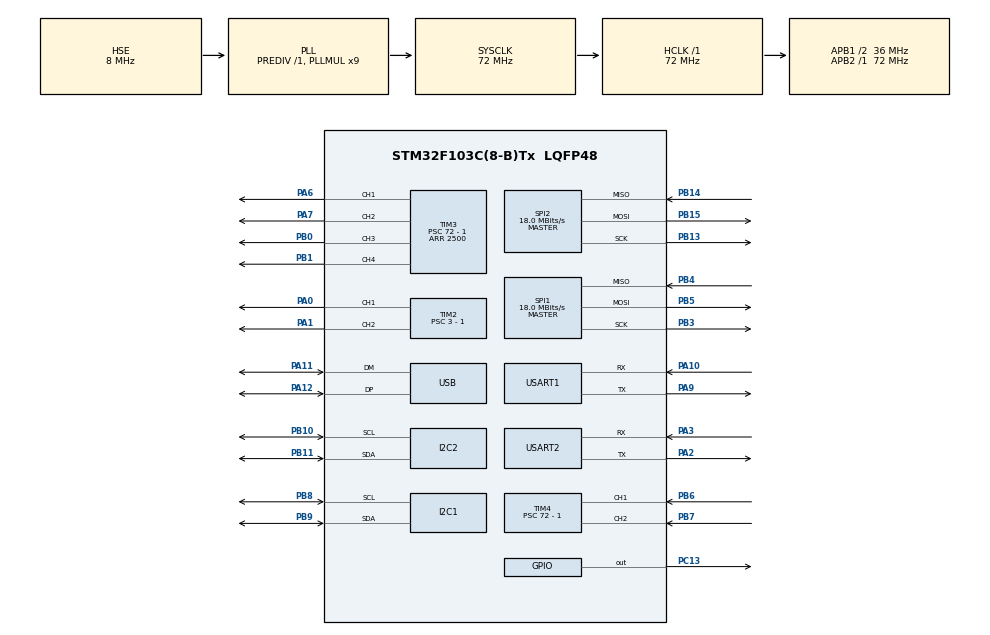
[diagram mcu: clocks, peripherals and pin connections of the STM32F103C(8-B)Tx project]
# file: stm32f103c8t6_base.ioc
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Dma.I2C1_TX.2.Direction=DMA_MEMORY_TO_PERIPH
Dma.I2C1_TX.2.Instance=DMA1_Channel6
Dma.I2C1_TX.2.MemDataAlignment=DMA_MDATAALIGN_BYTE
Dma.I2C1_TX.2.MemInc=DMA_MINC_ENABLE
Dma.I2C1_TX.2.Mode=DMA_NORMAL
Dma.I2C1_TX.2.PeriphDataAlignment=DMA_PDATAALIGN_BYTE
Dma.I2C1_TX.2.PeriphInc=DMA_PINC_DISABLE
Dma.I2C1_TX.2.Priority=DMA_PRIORITY_LOW
Dma.I2C2_TX.3.Direction=DMA_MEMORY_TO_PERIPH
Dma.I2C2_TX.3.Instance=DMA1_Channel4
Dma.I2C2_TX.3.MemDataAlignment=DMA_MDATAALIGN_BYTE
Dma.I2C2_TX.3.MemInc=DMA_MINC_ENABLE
Dma.I2C2_TX.3.Mode=DMA_NORMAL
Dma.I2C2_TX.3.PeriphDataAlignment=DMA_PDATAALIGN_BYTE
Dma.I2C2_TX.3.PeriphInc=DMA_PINC_DISABLE
Dma.I2C2_TX.3.Priority=DMA_PRIORITY_LOW
Dma.Request0=SPI1_RX
Dma.Request1=SPI1_TX
Dma.Request2=I2C1_TX
Dma.Request3=I2C2_TX
Dma.Request4=TIM2_CH1
Dma.Request5=TIM2_CH2/CH4
Dma.SPI1_RX.0.Direction=DMA_PERIPH_TO_MEMORY
Dma.SPI1_RX.0.Instance=DMA1_Channel2
Dma.SPI1_RX.0.MemDataAlignment=DMA_MDATAALIGN_BYTE
Dma.SPI1_RX.0.MemInc=DMA_MINC_ENABLE
Dma.SPI1_RX.0.Mode=DMA_NORMAL
Dma.SPI1_RX.0.PeriphDataAlignment=DMA_PDATAALIGN_BYTE
Dma.SPI1_RX.0.PeriphInc=DMA_PINC_DISABLE
Dma.SPI1_RX.0.Priority=DMA_PRIORITY_LOW
Dma.SPI1_TX.1.Direction=DMA_MEMORY_TO_PERIPH
Dma.SPI1_TX.1.Instance=DMA1_Channel3
Dma.SPI1_TX.1.MemDataAlignment=DMA_MDATAALIGN_BYTE
Dma.SPI1_TX.1.MemInc=DMA_MINC_ENABLE
Dma.SPI1_TX.1.Mode=DMA_NORMAL
Dma.SPI1_TX.1.PeriphDataAlignment=DMA_PDATAALIGN_BYTE
Dma.SPI1_TX.1.PeriphInc=DMA_PINC_DISABLE
Dma.SPI1_TX.1.Priority=DMA_PRIORITY_LOW
Dma.TIM2_CH1.4.Direction=DMA_MEMORY_TO_PERIPH
Dma.TIM2_CH1.4.Instance=DMA1_Channel5
Dma.TIM2_CH1.4.MemDataAlignment=DMA_MDATAALIGN_BYTE
Dma.TIM2_CH1.4.MemInc=DMA_MINC_ENABLE
Dma.TIM2_CH1.4.Mode=DMA_NORMAL
Dma.TIM2_CH1.4.PeriphDataAlignment=DMA_PDATAALIGN_HALFWORD
Dma.TIM2_CH1.4.PeriphInc=DMA_PINC_DISABLE
Dma.TIM2_CH1.4.Priority=DMA_PRIORITY_LOW
Dma.TIM2_CH2/CH4.5.Direction=DMA_MEMORY_TO_PERIPH
Dma.TIM2_CH2/CH4.5.Instance=DMA1_Channel7
Dma.TIM2_CH2/CH4.5.MemDataAlignment=DMA_MDATAALIGN_BYTE
Dma.TIM2_CH2/CH4.5.MemInc=DMA_MINC_ENABLE
Dma.TIM2_CH2/CH4.5.Mode=DMA_NORMAL
Dma.TIM2_CH2/CH4.5.PeriphDataAlignment=DMA_PDATAALIGN_HALFWORD
Dma.TIM2_CH2/CH4.5.PeriphInc=DMA_PINC_DISABLE
Dma.TIM2_CH2/CH4.5.Priority=DMA_PRIORITY_LOW
I2C1.I2C_Mode=I2C_Fast
I2C2.I2C_Mode=I2C_Fast
Mcu.Family=STM32F1
Mcu.Name=STM32F103C(8-B)Tx
Mcu.Package=LQFP48
NVIC.DMA1_Channel2_IRQn=true\:0\:0\:false\:false\:true
NVIC.DMA1_Channel3_IRQn=true\:0\:0\:false\:false\:true
NVIC.DMA1_Channel4_IRQn=true\:0\:0\:false\:false\:true
NVIC.DMA1_Channel5_IRQn=true\:0\:0\:false\:false\:true
NVIC.DMA1_Channel6_IRQn=true\:0\:0\:false\:false\:true
NVIC.DMA1_Channel7_IRQn=true\:0\:0\:false\:false\:true
NVIC.I2C1_ER_IRQn=true\:0\:0\:false\:false\:true
NVIC.I2C1_EV_IRQn=true\:0\:0\:false\:false\:true
NVIC.I2C2_ER_IRQn=true\:0\:0\:false\:false\:true
NVIC.I2C2_EV_IRQn=true\:0\:0\:false\:false\:true
NVIC.PriorityGroup=NVIC_PRIORITYGROUP_4
NVIC.SPI2_IRQn=true\:0\:0\:false\:false\:true
NVIC.TIM4_IRQn=true\:0\:0\:false\:false\:true
NVIC.USART1_IRQn=true\:0\:0\:false\:false\:true
NVIC.USART2_IRQn=true\:0\:0\:false\:false\:true
NVIC.USB_LP_CAN1_RX0_IRQn=true\:0\:0\:false\:false\:true
PA0-WKUP.Signal=S_TIM2_CH1_ETR
PA1.Signal=S_TIM2_CH2
PA10.Mode=Asynchronous
PA10.Signal=USART1_RX
PA11.Mode=Device
PA11.Signal=USB_DM
PA12.Mode=Device
PA12.Signal=USB_DP
PA13.Mode=Serial_Wire
PA13.Signal=SYS_JTMS-SWDIO
PA14.Mode=Serial_Wire
PA14.Signal=SYS_JTCK-SWCLK
PA2.Mode=Asynchronous
PA2.Signal=USART2_TX
PA3.Mode=Asynchronous
PA3.Signal=USART2_RX
PA6.Signal=S_TIM3_CH1
PA7.Signal=S_TIM3_CH2
PA9.Mode=Asynchronous
PA9.Signal=USART1_TX
PB0.Signal=S_TIM3_CH3
PB1.Signal=S_TIM3_CH4
PB10.Mode=I2C
PB10.Signal=I2C2_SCL
PB11.Mode=I2C
PB11.Signal=I2C2_SDA
PB13.Mode=Full_Duplex_Master
PB13.Signal=SPI2_SCK
PB14.Mode=Full_Duplex_Master
PB14.Signal=SPI2_MISO
PB15.Mode=Full_Duplex_Master
PB15.Signal=SPI2_MOSI
PB3.Mode=Full_Duplex_Master
PB3.Signal=SPI1_SCK
PB4.Mode=Full_Duplex_Master
PB4.Signal=SPI1_MISO
PB5.Mode=Full_Duplex_Master
PB5.Signal=SPI1_MOSI
PB6.Signal=S_TIM4_CH1
PB7.Signal=S_TIM4_CH2
PB8.Mode=I2C
PB8.Signal=I2C1_SCL
PB9.Mode=I2C
PB9.Signal=I2C1_SDA
PC13-TAMPER-RTC.Signal=GPIO_Output
PD0-OSC_IN.Mode=HSE-External-Oscillator
PD0-OSC_IN.Signal=RCC_OSC_IN
PD1-OSC_OUT.Mode=HSE-External-Oscillator
PD1-OSC_OUT.Signal=RCC_OSC_OUT
ProjectManager.HeapSize=0x200
ProjectManager.StackSize=0x400
ProjectManager.TargetToolchain=Makefile
RCC.AHBFreq_Value=72000000
RCC.APB1CLKDivider=RCC_HCLK_DIV2
RCC.APB1Freq_Value=36000000
RCC.APB1TimFreq_Value=72000000
RCC.APB2Freq_Value=72000000
RCC.APB2TimFreq_Value=72000000
RCC.HCLKFreq_Value=72000000
RCC.PLLMUL=RCC_PLL_MUL9
RCC.SYSCLKFreq_VALUE=72000000
RCC.SYSCLKSource=RCC_SYSCLKSOURCE_PLLCLK
RCC.USBFreq_Value=48000000
RCC.USBPrescaler=RCC_USBCLKSOURCE_PLL_DIV1_5
SH.S_TIM2_CH1_ETR.0=TIM2_CH1,PWM Generation1 CH1
SH.S_TIM2_CH2.0=TIM2_CH2,PWM Generation2 CH2
SH.S_TIM3_CH1.0=TIM3_CH1,PWM Generation1 CH1
SH.S_TIM3_CH2.0=TIM3_CH2,PWM Generation2 CH2
SH.S_TIM3_CH3.0=TIM3_CH3,PWM Generation3 CH3
SH.S_TIM3_CH4.0=TIM3_CH4,PWM Generation4 CH4
SH.S_TIM4_CH1.0=TIM4_CH1,Input_Capture1_from_TI1
SH.S_TIM4_CH2.0=TIM4_CH2,Input_Capture2_from_TI2
SPI1.BaudRatePrescaler=SPI_BAUDRATEPRESCALER_4
SPI1.CalculateBaudRate=18.0 MBits/s
SPI1.Direction=SPI_DIRECTION_2LINES
SPI1.Mode=SPI_MODE_MASTER
SPI1.VirtualType=VM_MASTER
SPI2.BaudRatePrescaler=SPI_BAUDRATEPRESCALER_2
SPI2.CalculateBaudRate=18.0 MBits/s
SPI2.Direction=SPI_DIRECTION_2LINES
SPI2.Mode=SPI_MODE_MASTER
SPI2.VirtualType=VM_MASTER
TIM1.AutoReloadPreload=TIM_AUTORELOAD_PRELOAD_ENABLE
TIM1.Period=65535
TIM1.Prescaler=72 - 1
TIM2.AutoReloadPreload=TIM_AUTORELOAD_PRELOAD_ENABLE
TIM2.Channel-PWM\ Generation1\ CH1=TIM_CHANNEL_1
TIM2.Channel-PWM\ Generation2\ CH2=TIM_CHANNEL_2
TIM2.Period=30 - 1
TIM2.Prescaler=3 - 1
TIM3.AutoReloadPreload=TIM_AUTORELOAD_PRELOAD_ENABLE
TIM3.Channel-PWM\ Generation1\ CH1=TIM_CHANNEL_1
TIM3.Channel-PWM\ Generation2\ CH2=TIM_CHANNEL_2
TIM3.Channel-PWM\ Generation3\ CH3=TIM_CHANNEL_3
TIM3.Channel-PWM\ Generation4\ CH4=TIM_CHANNEL_4
TIM3.Period=2500
TIM3.Prescaler=72 - 1
TIM4.Channel-Input_Capture1_from_TI1=TIM_CHANNEL_1
TIM4.Channel-Input_Capture2_from_TI2=TIM_CHANNEL_2
TIM4.Period=65535
TIM4.Prescaler=72 - 1
USART1.VirtualMode=VM_ASYNC
USART2.VirtualMode=VM_ASYNC
USB_DEVICE.CLASS_NAME_FS=CDC
USB_DEVICE.VirtualMode=Cdc
USB_DEVICE.VirtualModeFS=Cdc_FS
VP_TIM1_VS_ClockSourceINT.Mode=Internal
VP_TIM2_VS_ClockSourceINT.Mode=Internal
VP_TIM3_VS_ClockSourceINT.Mode=Internal
VP_TIM4_VS_ClockSourceINT.Mode=Internal
VP_USB_DEVICE_VS_USB_DEVICE_CDC_FS.Mode=CDC_FS
board=stm32f103c8t6_base

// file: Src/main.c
/**
  ******************************************************************************
  * File Name          : main.c
  * Description        : Main program body
  ******************************************************************************
  * This notice applies to any and all portions of this file
  * that are not between comment pairs USER CODE BEGIN and
  * USER CODE END. Other portions of this file, whether
  * inserted by the user or by software development tools
  * are owned by their respective copyright owners.
  *
  * Copyright (c) 2017 STMicroelectronics International N.V.
  * All rights reserved.
  *
  * Redistribution and use in source and binary forms, with or without
  * modification, are permitted, provided that the following conditions are met:
  *
  * 1. Redistribution of source code must retain the above copyright notice,
  *    this list of conditions and the following disclaimer.
  * 2. Redistributions in binary form must reproduce the above copyright notice,
  *    this list of conditions and the following disclaimer in the documentation
  *    and/or other materials provided with the distribution.
  * 3. Neither the name of STMicroelectronics nor the names of other
  *    contributors to this software may be used to endorse or promote products
  *    derived from this software without specific written permission.
  * 4. This software, including modifications and/or derivative works of this
  *    software, must execute solely and exclusively on microcontroller or
  *    microprocessor devices manufactured by or for STMicroelectronics.
  * 5. Redistribution and use of this software other than as permitted under
  *    this license is void and will automatically terminate your rights under
  *    this license.
  *
  * THIS SOFTWARE IS PROVIDED BY STMICROELECTRONICS AND CONTRIBUTORS "AS IS"
  * AND ANY EXPRESS, IMPLIED OR STATUTORY WARRANTIES, INCLUDING, BUT NOT
  * LIMITED TO, THE IMPLIED WARRANTIES OF MERCHANTABILITY, FITNESS FOR A
  * PARTICULAR PURPOSE AND NON-INFRINGEMENT OF THIRD PARTY INTELLECTUAL PROPERTY
  * RIGHTS ARE DISCLAIMED TO THE FULLEST EXTENT PERMITTED BY LAW. IN NO EVENT
  * SHALL STMICROELECTRONICS OR CONTRIBUTORS BE LIABLE FOR ANY DIRECT, INDIRECT,
  * INCIDENTAL, SPECIAL, EXEMPLARY, OR CONSEQUENTIAL DAMAGES (INCLUDING, BUT NOT
  * LIMITED TO, PROCUREMENT OF SUBSTITUTE GOODS OR SERVICES; LOSS OF USE, DATA,
  * OR PROFITS; OR BUSINESS INTERRUPTION) HOWEVER CAUSED AND ON ANY THEORY OF
  * LIABILITY, WHETHER IN CONTRACT, STRICT LIABILITY, OR TORT (INCLUDING
  * NEGLIGENCE OR OTHERWISE) ARISING IN ANY WAY OUT OF THE USE OF THIS SOFTWARE,
  * EVEN IF ADVISED OF THE POSSIBILITY OF SUCH DAMAGE.
  *
  ******************************************************************************
  */
#include "main.h"
#include "stm32f1xx_hal.h"
#include "dma.h"
#include "i2c.h"
#include "spi.h"
#include "tim.h"
#include "usart.h"
#include "usb_device.h"
#include "gpio.h"

#include "app.h"

/* USER CODE BEGIN PV */
/* Private variables ---------------------------------------------------------*/

/* USER CODE END PV */

void SystemClock_Config(void);

/* USER CODE BEGIN PFP */
/* Private function prototypes -----------------------------------------------*/

/* USER CODE END PFP */

int main(void)
{

  /* MCU Configuration----------------------------------------------------------*/

  /* Reset of all peripherals, Initializes the Flash interface and the Systick. */
  HAL_Init();

  app_init_f();

  /* Configure the system clock */
  SystemClock_Config();

  /* Initialize all configured peripherals */
  MX_GPIO_Init();
  MX_DMA_Init();
  MX_USART1_UART_Init();
  MX_USART2_UART_Init();
  MX_I2C1_Init();
  MX_SPI2_Init();
  MX_I2C2_Init();
  MX_TIM1_Init();
  MX_TIM3_Init();
  MX_SPI1_Init();
  MX_TIM2_Init();
  MX_TIM4_Init();
  MX_USB_DEVICE_Init();

  /* USER CODE BEGIN 2 */
  app_init_r();
  /* USER CODE END 2 */

  /* Infinite loop */
  /* USER CODE BEGIN WHILE */
  app_mainloop();
  /* USER CODE END WHILE */

}

/** System Clock Configuration
*/
void SystemClock_Config(void)
{

  RCC_OscInitTypeDef RCC_OscInitStruct;
  RCC_ClkInitTypeDef RCC_ClkInitStruct;
  RCC_PeriphCLKInitTypeDef PeriphClkInit;

    /**Initializes the CPU, AHB and APB busses clocks
    */
  RCC_OscInitStruct.OscillatorType = RCC_OSCILLATORTYPE_HSE;
  RCC_OscInitStruct.HSEState = RCC_HSE_ON;
  RCC_OscInitStruct.HSEPredivValue = RCC_HSE_PREDIV_DIV1;
  RCC_OscInitStruct.HSIState = RCC_HSI_ON;
  RCC_OscInitStruct.PLL.PLLState = RCC_PLL_ON;
  RCC_OscInitStruct.PLL.PLLSource = RCC_PLLSOURCE_HSE;
  RCC_OscInitStruct.PLL.PLLMUL = RCC_PLL_MUL9;
  if (HAL_RCC_OscConfig(&RCC_OscInitStruct) != HAL_OK)
  {
    _Error_Handler(__FILE__, __LINE__);
  }

    /**Initializes the CPU, AHB and APB busses clocks
    */
  RCC_ClkInitStruct.ClockType = RCC_CLOCKTYPE_HCLK|RCC_CLOCKTYPE_SYSCLK
                              |RCC_CLOCKTYPE_PCLK1|RCC_CLOCKTYPE_PCLK2;
  RCC_ClkInitStruct.SYSCLKSource = RCC_SYSCLKSOURCE_PLLCLK;
  RCC_ClkInitStruct.AHBCLKDivider = RCC_SYSCLK_DIV1;
  RCC_ClkInitStruct.APB1CLKDivider = RCC_HCLK_DIV2;
  RCC_ClkInitStruct.APB2CLKDivider = RCC_HCLK_DIV1;

  if (HAL_RCC_ClockConfig(&RCC_ClkInitStruct, FLASH_LATENCY_2) != HAL_OK)
  {
    _Error_Handler(__FILE__, __LINE__);
  }

  PeriphClkInit.PeriphClockSelection = RCC_PERIPHCLK_USB;
  PeriphClkInit.UsbClockSelection = RCC_USBCLKSOURCE_PLL_DIV1_5;
  if (HAL_RCCEx_PeriphCLKConfig(&PeriphClkInit) != HAL_OK)
  {
    _Error_Handler(__FILE__, __LINE__);
  }

    /**Configure the Systick interrupt time
    */
  HAL_SYSTICK_Config(HAL_RCC_GetHCLKFreq()/1000);

    /**Configure the Systick
    */
  HAL_SYSTICK_CLKSourceConfig(SYSTICK_CLKSOURCE_HCLK);

  /* SysTick_IRQn interrupt configuration */
  HAL_NVIC_SetPriority(SysTick_IRQn, 0, 0);
}

void _Error_Handler(char * file, int line)
{
  while(1)
  {
  }
}

/************************ (C) COPYRIGHT STMicroelectronics *****END OF FILE****/
